# nrf52820 register map
Vendor: Nordic Semiconductor; Series: nrf52; File version: 1
CPU: CM4 r0p1, little endian, MPU, no FPU, 3 interrupt priority bits
Registers are 32-bit, read-write, reset 0x0 unless marked. A register's access mark holds for its fields unless they carry their own. Offsets are from the block's base; [hi:lo] are bit positions; lines under a group give offsets from that group; {n}, {i} and the like mark numbered series; 'fields as' and 'values as' point back to an identical list.

## POWER — Power control
Base 0x40000000; alternate view of APPROTECT
0x78 TASKS_CONSTLAT wo — Enable Constant Latency mode
  [0] TASKS_CONSTLAT
    1=Trigger task
0x7C TASKS_LOWPWR wo — Enable Low-power mode (variable latency)
  [0] TASKS_LOWPWR
    1=Trigger task
0x108 EVENTS_POFWARN — Power failure warning
  [0] EVENTS_POFWARN
    0=NotGenerated (Event not generated); 1=Generated (Event generated)
0x114 EVENTS_SLEEPENTER — CPU entered WFI/WFE sleep
  [0] EVENTS_SLEEPENTER
    values as EVENTS_POFWARN.EVENTS_POFWARN
0x118 EVENTS_SLEEPEXIT — CPU exited WFI/WFE sleep
  [0] EVENTS_SLEEPEXIT
    values as EVENTS_POFWARN.EVENTS_POFWARN
0x11C EVENTS_USBDETECTED — Voltage supply detected on VBUS
  [0] EVENTS_USBDETECTED
    values as EVENTS_POFWARN.EVENTS_POFWARN
0x120 EVENTS_USBREMOVED — Voltage supply removed from VBUS
  [0] EVENTS_USBREMOVED
    values as EVENTS_POFWARN.EVENTS_POFWARN
0x124 EVENTS_USBPWRRDY — USB 3.3 V supply ready
  [0] EVENTS_USBPWRRDY
    values as EVENTS_POFWARN.EVENTS_POFWARN
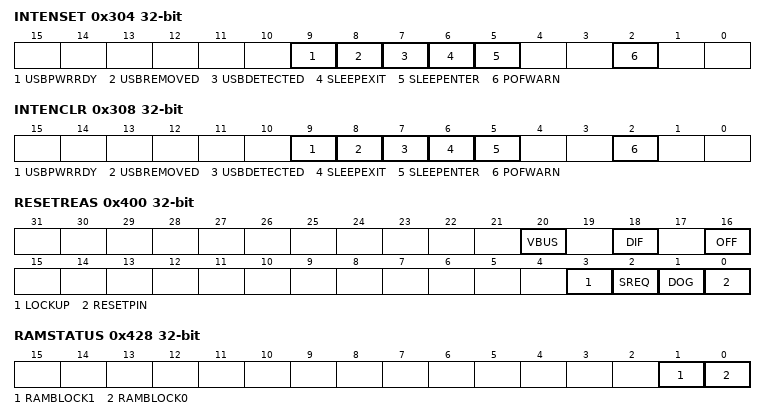
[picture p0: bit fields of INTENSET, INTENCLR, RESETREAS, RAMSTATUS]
0x304 INTENSET — Enable interrupt
  [all] fields
    on read: 0=Disabled (Read: Disabled); 1=Enabled (Read: Enabled) | on write: 1=Set (Enable)
  [9] USBPWRRDY — Write '1' to enable interrupt for event USBPWRRDY
  [8] USBREMOVED — Write '1' to enable interrupt for event USBREMOVED
  [7] USBDETECTED — Write '1' to enable interrupt for event USBDETECTED
  [6] SLEEPEXIT — Write '1' to enable interrupt for event SLEEPEXIT
  [5] SLEEPENTER — Write '1' to enable interrupt for event SLEEPENTER
  [2] POFWARN — Write '1' to enable interrupt for event POFWARN
0x308 INTENCLR — Disable interrupt
  [all] fields
    on read: 0=Disabled (Read: Disabled); 1=Enabled (Read: Enabled) | on write: 1=Clear (Disable)
  [9] USBPWRRDY — Write '1' to disable interrupt for event USBPWRRDY
  [8] USBREMOVED — Write '1' to disable interrupt for event USBREMOVED
  [7] USBDETECTED — Write '1' to disable interrupt for event USBDETECTED
  [6] SLEEPEXIT — Write '1' to disable interrupt for event SLEEPEXIT
  [5] SLEEPENTER — Write '1' to disable interrupt for event SLEEPENTER
  [2] POFWARN — Write '1' to disable interrupt for event POFWARN
0x400 RESETREAS — Reset reason
  [all] fields
    0=NotDetected; 1=Detected
  [20] VBUS — Reset due to wake up from System OFF mode by VBUS rising into valid range
  [18] DIF — Reset due to wake up from System OFF mode when wakeup is triggered from entering into debug interface mode
  [16] OFF — Reset due to wake up from System OFF mode when wakeup is triggered from DETECT signal from GPIO
  [3] LOCKUP — Reset from CPU lock-up detected
  [2] SREQ — Reset from soft reset detected
  [1] DOG — Reset from watchdog detected
  [0] RESETPIN — Reset from pin-reset detected
0x428 RAMSTATUS ro — Deprecated register - RAM status register
  [1] RAMBLOCK1 — RAM block 1 is on or off/powering up
    0=Off; 1=On
  [0] RAMBLOCK0 — RAM block 0 is on or off/powering up
    0=Off; 1=On
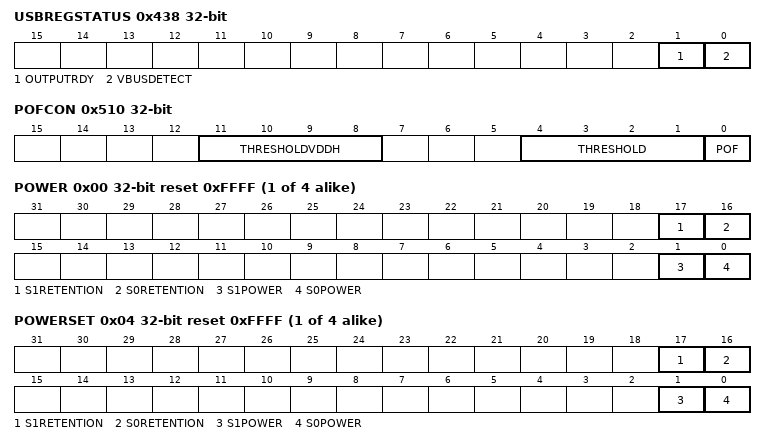
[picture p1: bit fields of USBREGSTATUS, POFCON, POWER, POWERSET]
0x438 USBREGSTATUS ro — USB supply status
  [1] OUTPUTRDY — USB supply output settling time elapsed
    0=NotReady (USBREG output settling time not elapsed); 1=Ready (USBREG output settling time elapsed (same information as USBPWRRDY event))
  [0] VBUSDETECT — VBUS input detection status (USBDETECTED and USBREMOVED events are derived from this information)
    0=NoVbus (VBUS voltage below valid threshold); 1=VbusPresent (VBUS voltage above valid threshold)
0x500 SYSTEMOFF wo
  [0] SYSTEMOFF — Enable System OFF mode
    1=Enter (Enable System OFF mode)
0x510 POFCON — Power-fail comparator configuration
  [11:8] THRESHOLDVDDH — Power-fail comparator threshold setting for high voltage mode (supply connected to VDDH only). This setting does not apply for normal voltage mode (supply connected to both VDD and VDDH).
    0=V27 (Set threshold to 2.7 V); 1=V28 (Set threshold to 2.8 V); 2=V29 (Set threshold to 2.9 V); 3=V30 (Set threshold to 3.0 V); 4=V31 (Set threshold to 3.1 V); 5=V32 (Set threshold to 3.2 V); 6=V33 (Set threshold to 3.3 V); 7=V34 (Set threshold to 3.4 V); 8=V35 (Set threshold to 3.5 V); 9=V36 (Set threshold to 3.6 V); 10=V37 (Set threshold to 3.7 V); 11=V38 (Set threshold to 3.8 V); 12=V39 (Set threshold to 3.9 V); 13=V40 (Set threshold to 4.0 V); 14=V41 (Set threshold to 4.1 V); 15=V42 (Set threshold to 4.2 V)
  [4:1] THRESHOLD — Power-fail comparator threshold setting. This setting applies both for normal voltage mode (supply connected to both VDD and VDDH) and high voltage mode (supply connected to VDDH only). Values 0-3 set threshold below 1.7 V and should not be used as brown out detection will be activated before power failure warning on such low voltages.
    4=V17 (Set threshold to 1.7 V); 5=V18 (Set threshold to 1.8 V); 6=V19 (Set threshold to 1.9 V); 7=V20 (Set threshold to 2.0 V); 8=V21 (Set threshold to 2.1 V); 9=V22 (Set threshold to 2.2 V); 10=V23 (Set threshold to 2.3 V); 11=V24 (Set threshold to 2.4 V); 12=V25 (Set threshold to 2.5 V); 13=V26 (Set threshold to 2.6 V); 14=V27 (Set threshold to 2.7 V); 15=V28 (Set threshold to 2.8 V)
  [0] POF — Enable or disable power failure warning
    0=Disabled; 1=Enabled
0x51C GPREGRET — General purpose retention register
  [7:0] GPREGRET
0x520 GPREGRET2 — General purpose retention register
  [7:0] GPREGRET
0x578 DCDCEN — Enable DC/DC converter for REG1 stage
  [0] DCDCEN — Enable DC/DC converter for REG1 stage.
    0=Disabled; 1=Enabled
0x640 MAINREGSTATUS ro — Main supply status
  [0] MAINREGSTATUS
    0=Normal voltage mode. Voltage supplied on VDD.; 1=High voltage mode. Voltage supplied on VDDH.
{0x900+0x10*i} RAM[{i}] (i=0..3) group — Unspecified
  0x00 POWER reset 0xFFFF — Description cluster: RAMn power control register
    [all] fields
      0=Off; 1=On
    [17] S1RETENTION — Keep retention on RAM section S1 when RAM section is off
    [16] S0RETENTION — Keep retention on RAM section S0 when RAM section is off
    [1] S1POWER — Keep RAM section S1 on or off in System ON mode.
    [0] S0POWER — Keep RAM section S0 on or off in System ON mode.
  0x04 POWERSET wo reset 0xFFFF — Description cluster: RAMn power control set register
    [all] fields
      1=On
    [17] S1RETENTION — Keep retention on RAM section S1 when RAM section is switched off
    [16] S0RETENTION — Keep retention on RAM section S0 when RAM section is switched off
    [1] S1POWER — Keep RAM section S1 of RAMn on or off in System ON mode
    [0] S0POWER — Keep RAM section S0 of RAMn on or off in System ON mode
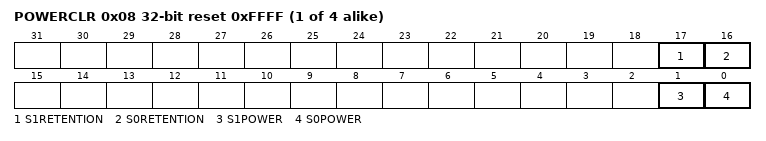
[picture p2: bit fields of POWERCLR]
  0x08 POWERCLR wo reset 0xFFFF — Description cluster: RAMn power control clear register
    [all] fields
      1=Off
    [17] S1RETENTION — Keep retention on RAM section S1 when RAM section is switched off
    [16] S0RETENTION — Keep retention on RAM section S0 when RAM section is switched off
    [1] S1POWER — Keep RAM section S1 of RAMn on or off in System ON mode
    [0] S0POWER — Keep RAM section S0 of RAMn on or off in System ON mode
